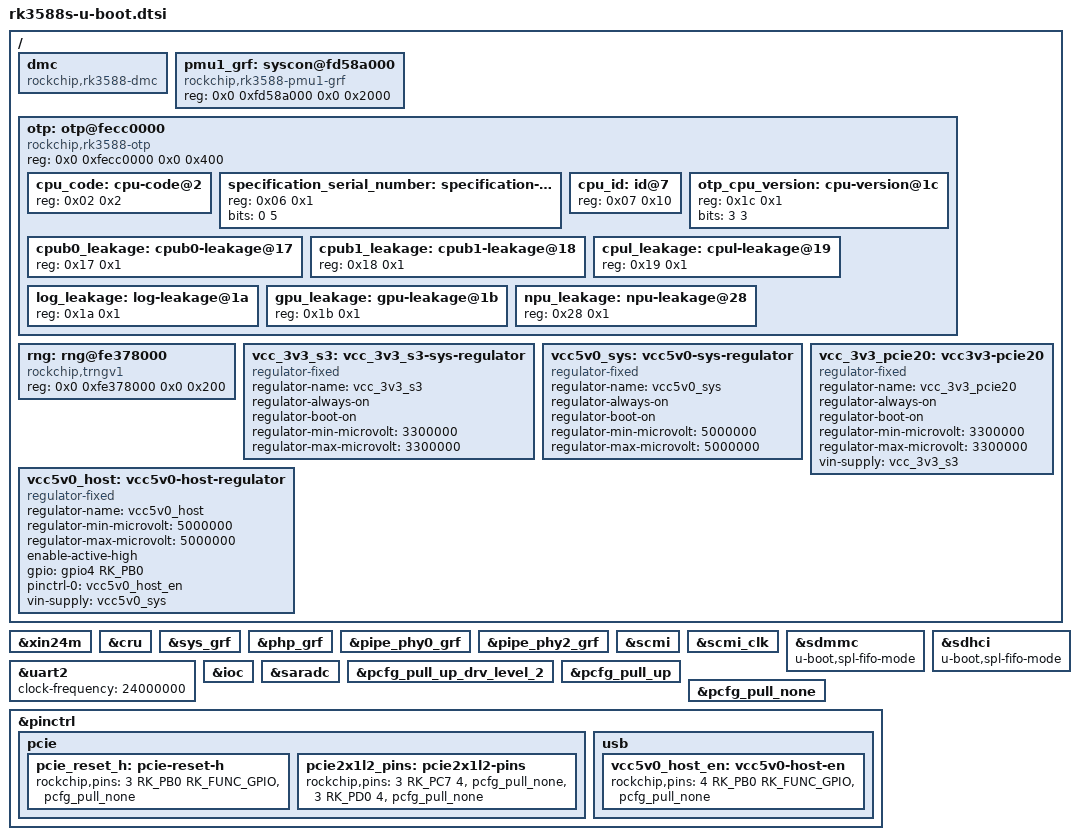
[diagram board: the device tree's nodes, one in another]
// SPDX-License-Identifier: (GPL-2.0+ OR MIT)
/*
 * Copyright (c) 2022 Edgeble AI Technologies Pvt. Ltd.
 */

#include "rockchip-u-boot.dtsi"
#include <dt-bindings/phy/phy.h>

/ {
	dmc {
		compatible = "rockchip,rk3588-dmc";
		bootph-all;
		status = "okay";
	};

	pmu1_grf: syscon@fd58a000 {
		bootph-all;
		compatible = "rockchip,rk3588-pmu1-grf", "syscon";
		reg = <0x0 0xfd58a000 0x0 0x2000>;
	};

	otp: otp@fecc0000 {
		compatible = "rockchip,rk3588-otp";
		reg = <0x0 0xfecc0000 0x0 0x400>;
		#address-cells = <1>;
		#size-cells = <1>;
		status = "okay";
		bootph-all;

		cpu_code: cpu-code@2 {
			bootph-all;
			reg = <0x02 0x2>;
		};
		specification_serial_number: specification-serial-number@6 {
			bootph-all;
			reg = <0x06 0x1>;
			bits = <0 5>;
		};
		cpu_id: id@7 {
			bootph-all;
			reg = <0x07 0x10>;
		};
		otp_cpu_version: cpu-version@1c {
			bootph-all;
			reg = <0x1c 0x1>;
			bits = <3 3>;
		};
		cpub0_leakage: cpub0-leakage@17 {
			bootph-all;
			reg = <0x17 0x1>;
		};
		cpub1_leakage: cpub1-leakage@18 {
			bootph-all;
			reg = <0x18 0x1>;
		};
		cpul_leakage: cpul-leakage@19 {
			bootph-all;
			reg = <0x19 0x1>;
		};
		log_leakage: log-leakage@1a {
			bootph-all;
			reg = <0x1a 0x1>;
		};
		gpu_leakage: gpu-leakage@1b {
			bootph-all;
			reg = <0x1b 0x1>;
		};
		npu_leakage: npu-leakage@28 {
			bootph-all;
			reg = <0x28 0x1>;
		};
	};

	rng: rng@fe378000 {
		compatible = "rockchip,trngv1";
		reg = <0x0 0xfe378000 0x0 0x200>;
		status = "disabled";
	};

        vcc_3v3_s3: vcc_3v3_s3-sys-regulator {
                compatible = "regulator-fixed";
                regulator-name = "vcc_3v3_s3";
                regulator-always-on;
                regulator-boot-on;
                regulator-min-microvolt = <3300000>;
                regulator-max-microvolt = <3300000>;
        };

        vcc5v0_sys: vcc5v0-sys-regulator {
                compatible = "regulator-fixed";
                regulator-name = "vcc5v0_sys";
                regulator-always-on;
                regulator-boot-on;
                regulator-min-microvolt = <5000000>;
                regulator-max-microvolt = <5000000>;
        };

	vcc_3v3_pcie20: vcc3v3-pcie20 {
                compatible = "regulator-fixed";
                regulator-name = "vcc_3v3_pcie20";
                regulator-always-on;
                regulator-boot-on;
                regulator-min-microvolt = <3300000>;
                regulator-max-microvolt = <3300000>;
                vin-supply = <&vcc_3v3_s3>;
        };

        vcc5v0_host: vcc5v0-host-regulator {
                compatible = "regulator-fixed";
                regulator-name = "vcc5v0_host";
                regulator-min-microvolt = <5000000>;
                regulator-max-microvolt = <5000000>;
                enable-active-high;
                gpio = <&gpio4 RK_PB0 GPIO_ACTIVE_HIGH>;
                pinctrl-names = "default";
                pinctrl-0 = <&vcc5v0_host_en>;
                vin-supply = <&vcc5v0_sys>;
        };
};

&xin24m {
	bootph-all;
	status = "okay";
};

&cru {
	bootph-all;
	status = "okay";
};

&sys_grf {
	bootph-all;
	status = "okay";
};

&php_grf {
	bootph-all;
        status = "okay";
};

&pipe_phy0_grf {
	bootph-all;
        status = "okay";
};

&pipe_phy2_grf {
	bootph-all;
        status = "okay";
};

&rng {
	bootph-all;
        status = "okay";
};

&scmi {
	bootph-all;
};

&scmi_clk {
	bootph-all;
};

&sdmmc {
	bootph-all;
	u-boot,spl-fifo-mode;
};

&sdhci {
	bootph-all;
	u-boot,spl-fifo-mode;
};

&uart2 {
	clock-frequency = <24000000>;
	bootph-all;
	status = "okay";
};

&ioc {
	bootph-all;
};

&saradc {
	bootph-all;
	status = "okay";
};

&pcfg_pull_up_drv_level_2 {
	bootph-all;
};

&pcfg_pull_up {
	bootph-all;
};

&pcfg_pull_none {
	bootph-all;
};

&pinctrl {
        bootph-all;

        pcie {
                pcie_reset_h: pcie-reset-h {
                        rockchip,pins = <3 RK_PB0 RK_FUNC_GPIO &pcfg_pull_none>;
                };

                pcie2x1l2_pins: pcie2x1l2-pins {
                        rockchip,pins = <3 RK_PC7 4 &pcfg_pull_none>,
                                        <3 RK_PD0 4 &pcfg_pull_none>;
                };
        };

        usb {
                vcc5v0_host_en: vcc5v0-host-en {
                        rockchip,pins = <4 RK_PB0 RK_FUNC_GPIO &pcfg_pull_none>;
                };
        };
};
